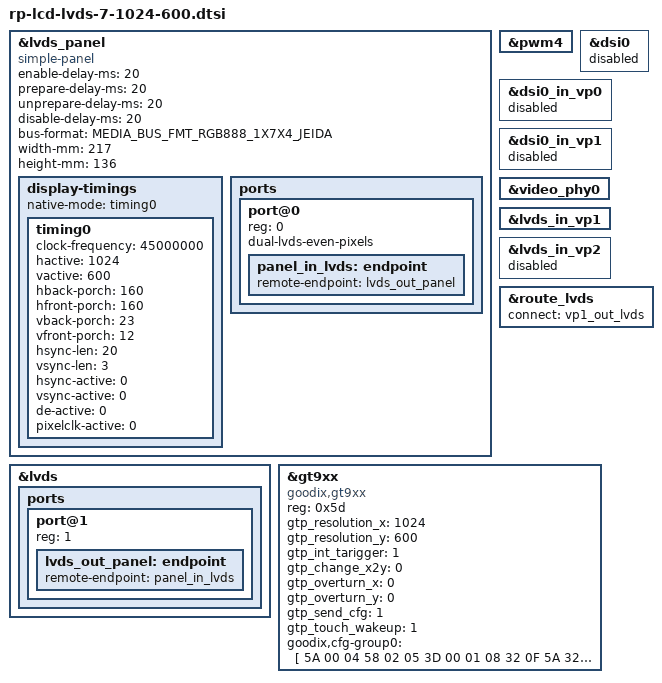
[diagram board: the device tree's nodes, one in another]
/**
 *  rpdzkj lcd configuration
 */
 
#include <dt-bindings/display/media-bus-format.h>
#include "rp-lcd-hdmi.dtsi"     //include for default support hdmi display
#define RP_SINGLE_LCD

&lvds_panel {
	status = "okay";
	compatible = "simple-panel";
	enable-delay-ms = <20>;
	prepare-delay-ms = <20>;
	unprepare-delay-ms = <20>;
	disable-delay-ms = <20>;
	bus-format = <MEDIA_BUS_FMT_RGB888_1X7X4_JEIDA>;
	width-mm = <217>;
	height-mm = <136>;
		
		/*
		 * power-supply = <>;
		 * reset-gpios = <>;
		 *
		 * lcd reset pin and power supply
		 * please refer to ***-lcd-gpio.dtsi
		 * that included in main dts.
		 */
		
	display-timings {
		native-mode = <&timing0>;

		timing0: timing0 {
			clock-frequency = <45000000>;
			hactive = <1024>;
			vactive = <600>;
			hback-porch = <160>;
			hfront-porch = <160>;
			vback-porch = <23>;
			vfront-porch = <12>;
			hsync-len = <20>;
			vsync-len = <3>;
			hsync-active = <0>;
			vsync-active = <0>;
			de-active = <0>;
			pixelclk-active = <0>;
		};
	};

	ports {
		#address-cells = <1>;
		#size-cells = <0>;

		port@0 {
			reg = <0>;
			dual-lvds-even-pixels;
			panel_in_lvds: endpoint {
				remote-endpoint = <&lvds_out_panel>;
			};
		};
	};
};

&lvds {
	status = "okay";
	ports {
		port@1 {
			reg = <1>;

			lvds_out_panel: endpoint {
				remote-endpoint = <&panel_in_lvds>;
			};
		};
	};
};




&pwm4 {
	status = "okay";
};

&dsi0 {
	status = "disabled";
};

&dsi0_in_vp0 {
	status = "disabled";
};

&dsi0_in_vp1 {
	status = "disabled";
};

&video_phy0 {
	status = "okay";
};

&lvds_in_vp1 {
	status = "okay";
};

&lvds_in_vp2 {
	status = "disabled";
};

&route_lvds {
	status = "okay";
	connect = <&vp1_out_lvds>;
};


&gt9xx {
	status = "okay";
	compatible = "goodix,gt9xx";
	reg = <0x5d>;
	gtp_resolution_x = <1024>;
	gtp_resolution_y = <600>;
	gtp_int_tarigger = <1>;
	gtp_change_x2y = <0>;
	gtp_overturn_x = <0>;
	gtp_overturn_y = <0>;
	gtp_send_cfg = <1>;
	gtp_touch_wakeup = <1>;
	//goodix_rst_gpio = <&gpio0 RK_PB6 GPIO_ACTIVE_HIGH>;
	//goodix_irq_gpio = <&gpio0 RK_PA5 IRQ_TYPE_EDGE_FALLING>;

		/**
		 * goodix_rst_gpio = <>;
		 * goodix_irq_gpio = <>;
		 *
		 * touch panel interrupt and reset pin
		 * please refer to ***-lcd-gpio.dtsi
		 * that included in main dts.
		 */

	goodix,cfg-group0 = [
				5A 00 04 58 02 05 3D 00 01
				08 32 0F 5A 32 03 05 00 00
				00 00 02 00 00 18 1A 1E 14
				87 29 0A 55 57 B5 06 00 00
				00 20 33 1C 14 01 00 0F 00
				2B FF 7F 19 46 32 3C 78 94
				D5 02 08 00 00 04 98 40 00
				8A 4A 00 80 55 00 77 61 00
				6F 70 00 6F 00 00 00 00 F0
				40 30 FF FF 27 00 00 00 00
				00 00 00 00 00 00 00 00 00
				00 00 00 00 00 00 00 00 00
				00 00 00 00 02 04 06 08 0A
				0C 0E 10 12 14 FF FF FF FF
				00 00 00 00 00 00 00 00 00
				00 00 00 00 00 00 00 00 02
				04 06 08 0A 0C 1D 1E 1F 20
				21 22 24 26 28 29 2A FF FF
				FF FF FF FF FF FF 00 00 00
				00 00 00 00 00 00 00 00 00
				00 00 00 00 6F 01
			];

};
